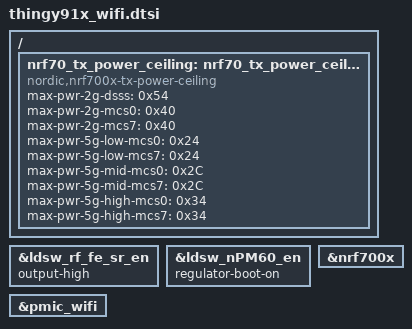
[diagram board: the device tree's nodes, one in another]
/*
 * Copyright (c) 2024 Nordic Semiconductor
 * SPDX-License-Identifier: LicenseRef-Nordic-5-Clause
 */

/* enable short range rf */
&ldsw_rf_fe_sr_en {
	/delete-property/ output-low;
	output-high;
};

/* set pmic_wifi enable signal  */
&ldsw_nPM60_en {
	regulator-boot-on;
};

/* enable pmic_wifi */
&pmic_wifi {
	status = "okay";
};

/* enable nrf70 */
&nrf700x {
	status = "okay";
};

/ {
	nrf70_tx_power_ceiling: nrf70_tx_power_ceiling_node {
		status = "okay";
		compatible = "nordic,nrf700x-tx-power-ceiling";
		max-pwr-2g-dsss = <0x54>;
		max-pwr-2g-mcs0 = <0x40>;
		max-pwr-2g-mcs7 = <0x40>;
		max-pwr-5g-low-mcs0 = <0x24>;
		max-pwr-5g-low-mcs7 = <0x24>;
		max-pwr-5g-mid-mcs0 = <0x2C>;
		max-pwr-5g-mid-mcs7 = <0x2C>;
		max-pwr-5g-high-mcs0 = <0x34>;
		max-pwr-5g-high-mcs7 = <0x34>;
	};
};
